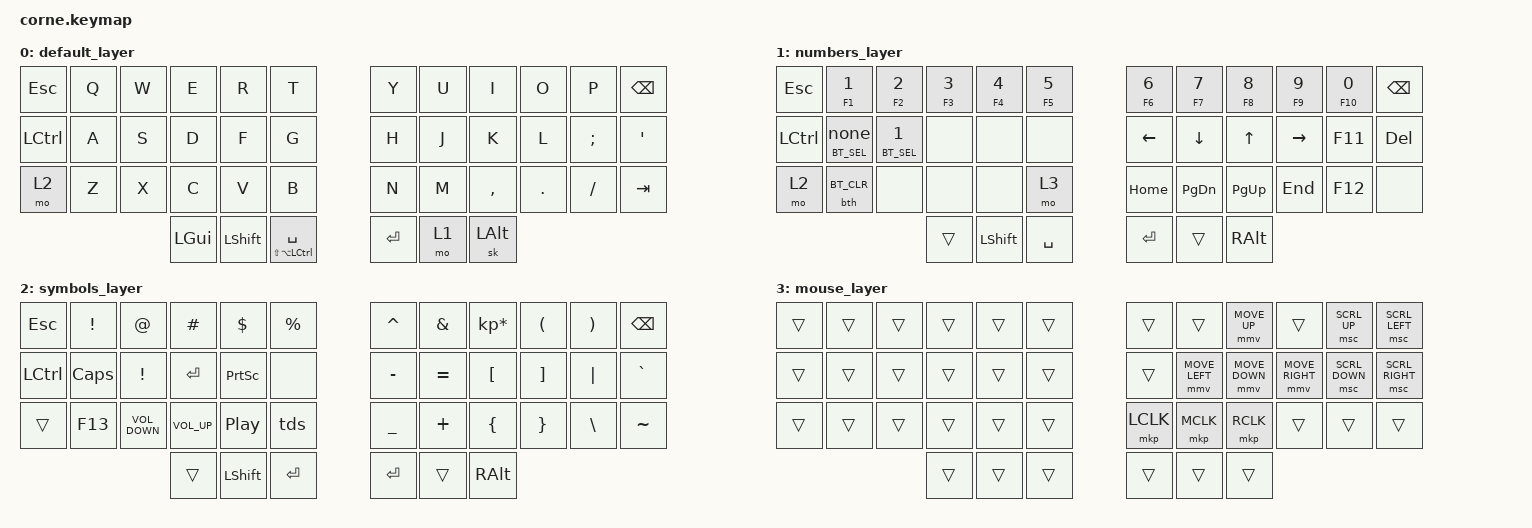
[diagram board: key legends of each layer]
/*
 * Copyright (c) 2020 The ZMK Contributors
 *
 * SPDX-License-Identifier: MIT
 */

#include <behaviors.dtsi>
#include <dt-bindings/zmk/bt.h>
#include <dt-bindings/zmk/keys.h>
#include <dt-bindings/zmk/pointing.h>

/ {
    behaviors {
        hm: homerow_mods {
            compatible = "zmk,behavior-hold-tap";
            label = "HOMEROW_MODS";
            #binding-cells = <2>;
            tapping-term-ms = <200>;
            quick-tap-ms = <200>;
            flavor = "tap-preferred";
            bindings = <&kp>, <&kp>;
        };

        shm: slow_homerow_mods {
            compatible = "zmk,behavior-hold-tap";
            label = "SLOW_HOMEROW_MODS";
            #binding-cells = <2>;
            tapping-term-ms = <500>;
            quick-tap-ms = <500>;
            flavor = "tap-preferred";
            bindings = <&kp>, <&kp>;
        };

        tds: tap_dance_next_prev {
            compatible = "zmk,behavior-tap-dance";
            label = "TAP_DANCE_NEXT_PREV";
            #binding-cells = <0>;
            tapping-term-ms = <200>;
            bindings = <&kp C_NEXT>, <&kp C_PREVIOUS>;
        };

        bth: bt_hold {
            compatible = "zmk,behavior-hold-tap";
            label = "BT_HOLD";
            #binding-cells = <2>;
            tapping-term-ms = <2000>;
            quick-tap-ms = <0>;
            flavor = "tap-preferred";
            bindings = <&bt>, <&none>;
        };
    };

    keymap {
        compatible = "zmk,keymap";

        default_layer {
            bindings = <
&kp ESC    &kp Q  &kp W  &kp E     &kp R           &kp T                       &kp Y    &kp U  &kp I      &kp O    &kp P     &kp BSPC
&kp LCTRL  &kp A  &kp S  &kp D     &kp F           &kp G                       &kp H    &kp J  &kp K      &kp L    &kp SEMI  &kp SQT
&mo 2      &kp Z  &kp X  &kp C     &kp V           &kp B                       &kp N    &kp M  &kp COMMA  &kp DOT  &kp FSLH  &kp TAB
                         &kp LGUI  &kp LEFT_SHIFT  &shm LS(LA(LCTRL)) SPACE    &kp RET  &mo 1  &sk LALT
            >;
        };

        numbers_layer {
            bindings = <
&kp ESC    &hm F1 N1      &hm F2 N2      &hm F3 N3  &hm F4 N4       &hm F5 N5    &hm F6 N6  &hm F7 N7      &hm F8 N8    &hm F9 N9  &hm F10 N0  &kp BSPC
&kp LCTRL  &bth BT_SEL 0  &bth BT_SEL 1  &none      &none           &none        &kp LEFT   &kp DOWN       &kp UP       &kp RIGHT  &kp F11     &kp DEL
&mo 2      &bth BT_CLR    &none          &none      &none           &mo 3        &kp HOME   &kp PAGE_DOWN  &kp PAGE_UP  &kp END    &kp F12     &none
                                         &trans     &kp LEFT_SHIFT  &kp SPACE    &kp RET    &trans         &kp RALT
            >;
        };

        symbols_layer {
            bindings = <
&kp ESC    &kp EXCL      &kp AT             &kp HASH      &kp DLLR        &kp PRCNT    &kp CARET  &kp AMPS   &kp KP_MULTIPLY  &kp LPAR  &kp RPAR  &kp BSPC
&kp LCTRL  &kp CAPSLOCK  &kp EXCL           &kp RET       &kp PSCRN       &none        &kp MINUS  &kp EQUAL  &kp LBKT         &kp RBKT  &kp PIPE  &kp GRAVE
&trans     &kp F13       &kp C_VOLUME_DOWN  &kp C_VOL_UP  &kp C_PP        &tds         &kp UNDER  &kp PLUS   &kp LBRC         &kp RBRC  &kp BSLH  &kp TILDE
                                            &trans        &kp LEFT_SHIFT  &kp ENTER    &kp RET    &trans     &kp RALT
            >;
        };

        mouse_layer {
            bindings = <
&trans  &trans  &trans  &trans  &trans  &trans    &trans     &trans          &mmv MOVE_UP    &trans           &msc SCRL_UP    &msc SCRL_LEFT
&trans  &trans  &trans  &trans  &trans  &trans    &trans     &mmv MOVE_LEFT  &mmv MOVE_DOWN  &mmv MOVE_RIGHT  &msc SCRL_DOWN  &msc SCRL_RIGHT
&trans  &trans  &trans  &trans  &trans  &trans    &mkp LCLK  &mkp MCLK       &mkp RCLK       &trans           &trans          &trans
                        &trans  &trans  &trans    &trans     &trans          &trans
            >;
        };
    };
};
